# LRFDMDM register map
Vendor: Texas Instruments
Registers are 32-bit, access per field, reset 0x0 unless marked. A register's access mark holds for its fields unless they carry their own. Offsets are as the file gives them; [hi:lo] are bit positions; {n}, {i} and the like mark numbered series; 'fields as' and 'values as' point back to an identical list.

## LRFDMDM (part 3 of 3)
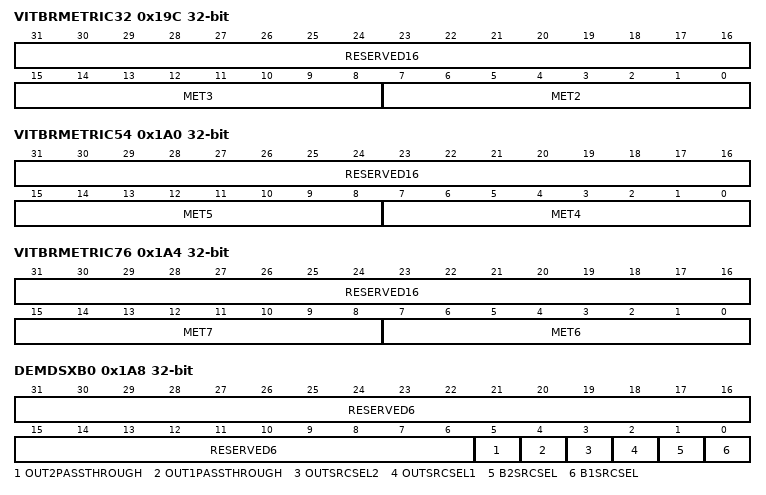
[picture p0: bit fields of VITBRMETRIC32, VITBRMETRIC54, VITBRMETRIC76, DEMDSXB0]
0x19C VITBRMETRIC32 — Internal. Only to be used through TI provided API.
  [31:16] RESERVED16 ro — Internal. Only to be used through TI provided API.
  [15:8] MET3 rw — Internal. Only to be used through TI provided API.
    255=ALLONES (Internal. Only to be used through TI provided API.); 0=ALLZEROS (Internal. Only to be used through TI provided API.)
  [7:0] MET2 rw — Internal. Only to be used through TI provided API.
    values as MET3
0x1A0 VITBRMETRIC54 — Internal. Only to be used through TI provided API.
  [31:16] RESERVED16 ro — Internal. Only to be used through TI provided API.
  [15:8] MET5 rw — Internal. Only to be used through TI provided API.
    values as VITBRMETRIC32.MET3
  [7:0] MET4 rw — Internal. Only to be used through TI provided API.
    values as VITBRMETRIC32.MET3
0x1A4 VITBRMETRIC76 — Internal. Only to be used through TI provided API.
  [31:16] RESERVED16 ro — Internal. Only to be used through TI provided API.
  [15:8] MET7 rw — Internal. Only to be used through TI provided API.
    values as VITBRMETRIC32.MET3
  [7:0] MET6 rw — Internal. Only to be used through TI provided API.
    values as VITBRMETRIC32.MET3
0x1A8 DEMDSXB0 — Internal. Only to be used through TI provided API.
  [31:6] RESERVED6 ro — Internal. Only to be used through TI provided API.
  [5] OUT2PASSTHROUGH rw — Internal. Only to be used through TI provided API.
    1=ONE (Internal. Only to be used through TI provided API.); 0=ZERO (Internal. Only to be used through TI provided API.)
  [4] OUT1PASSTHROUGH rw — Internal. Only to be used through TI provided API.
    values as OUT2PASSTHROUGH
  [3] OUTSRCSEL2 rw — Internal. Only to be used through TI provided API.
    1=MAFI (Internal. Only to be used through TI provided API.); 0=FIFE (Internal. Only to be used through TI provided API.)
  [2] OUTSRCSEL1 rw — Internal. Only to be used through TI provided API.
    values as OUTSRCSEL2
  [1] B2SRCSEL rw — Internal. Only to be used through TI provided API.
    1=FIFE (Internal. Only to be used through TI provided API.); 0=INPUT (Internal. Only to be used through TI provided API.)
  [0] B1SRCSEL rw — Internal. Only to be used through TI provided API.
    1=MAFI (Internal. Only to be used through TI provided API.); 0=INPUT (Internal. Only to be used through TI provided API.)
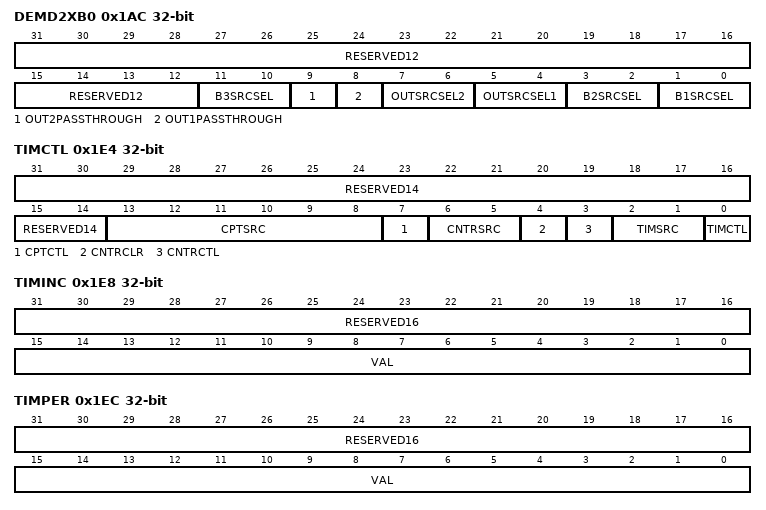
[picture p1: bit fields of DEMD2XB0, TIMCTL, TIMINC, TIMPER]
0x1AC DEMD2XB0 — Internal. Only to be used through TI provided API.
  [31:12] RESERVED12 ro — Internal. Only to be used through TI provided API.
  [11:10] B3SRCSEL rw — Internal. Only to be used through TI provided API.
    2=STIM (Internal. Only to be used through TI provided API.); 1=MAFC (Internal. Only to be used through TI provided API.); 0=INPUT (Internal. Only to be used through TI provided API.)
  [9] OUT2PASSTHROUGH rw — Internal. Only to be used through TI provided API.
  [8] OUT1PASSTHROUGH rw — Internal. Only to be used through TI provided API.
  [7:6] OUTSRCSEL2 rw — Internal. Only to be used through TI provided API.
    2=PDIF2 (Internal. Only to be used through TI provided API.); 1=STIM (Internal. Only to be used through TI provided API.); 0=MAFC (Internal. Only to be used through TI provided API.)
  [5:4] OUTSRCSEL1 rw — Internal. Only to be used through TI provided API.
    values as OUTSRCSEL2
  [3:2] B2SRCSEL rw — Internal. Only to be used through TI provided API.
    2=PDIF2 (Internal. Only to be used through TI provided API.); 1=MAFC (Internal. Only to be used through TI provided API.); 0=INPUT (Internal. Only to be used through TI provided API.)
  [1:0] B1SRCSEL rw — Internal. Only to be used through TI provided API.
    2=PDIF2 (Internal. Only to be used through TI provided API.); 1=STIM (Internal. Only to be used through TI provided API.); 0=INPUT (Internal. Only to be used through TI provided API.)
0x1E4 TIMCTL — Internal. Only to be used through TI provided API.
  [31:14] RESERVED14 ro — Internal. Only to be used through TI provided API.
  [13:8] CPTSRC rw — Internal. Only to be used through TI provided API.
    63=ALLONES (Internal. Only to be used through TI provided API.); 0=ALLZEROS (Internal. Only to be used through TI provided API.)
  [7] CPTCTL rw — Internal. Only to be used through TI provided API.
    1=EN (Internal. Only to be used through TI provided API.); 0=DIS (Internal. Only to be used through TI provided API.)
  [6:5] CNTRSRC rw — Internal. Only to be used through TI provided API.
    3=CLK4BAUDF (Internal. Only to be used through TI provided API.); 2=CLK4BAUD (Internal. Only to be used through TI provided API.); 1=CLKBAUD (Internal. Only to be used through TI provided API.); 0=CLK (Internal. Only to be used through TI provided API.)
  [4] CNTRCLR rw — Internal. Only to be used through TI provided API.
    values as DEMDSXB0.OUT2PASSTHROUGH
  [3] CNTRCTL rw — Internal. Only to be used through TI provided API.
    values as DEMDSXB0.OUT2PASSTHROUGH
  [2:1] TIMSRC rw — Internal. Only to be used through TI provided API.
    values as CNTRSRC
  [0] TIMCTL rw — Internal. Only to be used through TI provided API.
    values as CPTCTL
0x1E8 TIMINC — Internal. Only to be used through TI provided API.
  [31:16] RESERVED16 ro — Internal. Only to be used through TI provided API.
  [15:0] VAL rw — Internal. Only to be used through TI provided API.
    0xFFFF=ALLONES (Internal. Only to be used through TI provided API.); 0=ALLZEROS (Internal. Only to be used through TI provided API.)
0x1EC TIMPER — Internal. Only to be used through TI provided API.
  fields as TIMINC
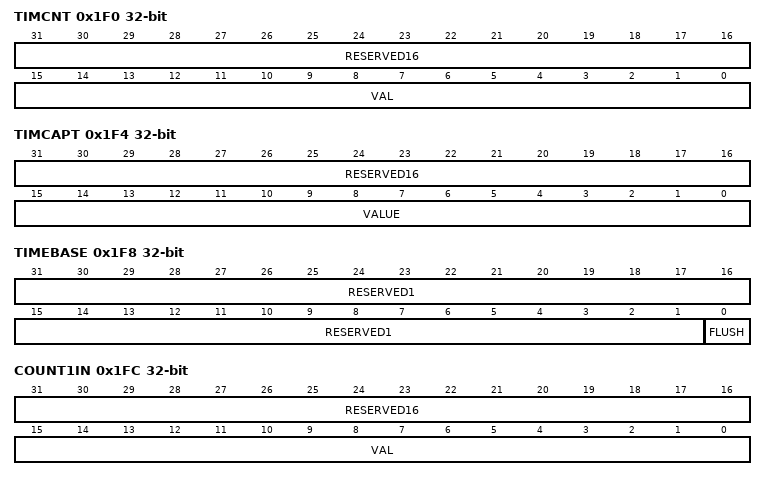
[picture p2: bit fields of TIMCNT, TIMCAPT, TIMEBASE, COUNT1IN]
0x1F0 TIMCNT ro — Internal. Only to be used through TI provided API.
  [31:16] RESERVED16 — Internal. Only to be used through TI provided API.
  [15:0] VAL — Internal. Only to be used through TI provided API.
    values as TIMINC.VAL
0x1F4 TIMCAPT ro — Internal. Only to be used through TI provided API.
  [31:16] RESERVED16 — Internal. Only to be used through TI provided API.
  [15:0] VALUE — Internal. Only to be used through TI provided API.
    values as TIMINC.VAL
0x1F8 TIMEBASE — Internal. Only to be used through TI provided API.
  [31:1] RESERVED1 ro — Internal. Only to be used through TI provided API.
  [0] FLUSH wo — Internal. Only to be used through TI provided API.
    values as DEMDSXB0.OUT2PASSTHROUGH
0x1FC COUNT1IN — Internal. Only to be used through TI provided API.
  fields as TIMINC
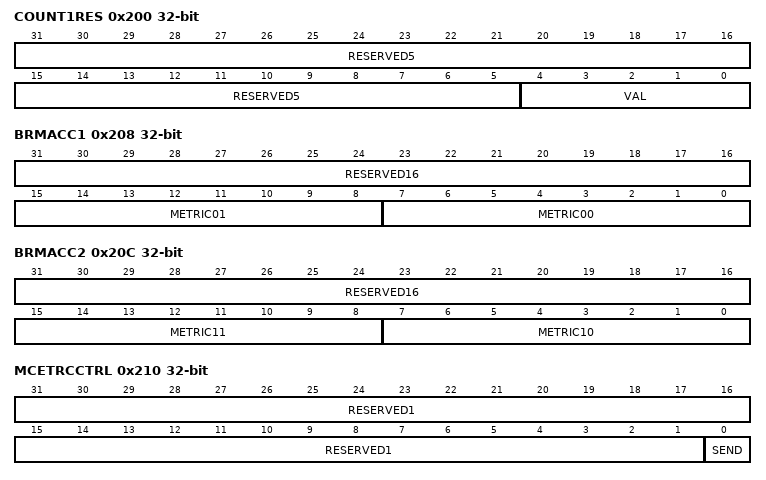
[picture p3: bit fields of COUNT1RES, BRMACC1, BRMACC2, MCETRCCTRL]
0x200 COUNT1RES ro — Internal. Only to be used through TI provided API.
  [31:5] RESERVED5 — Internal. Only to be used through TI provided API.
  [4:0] VAL — Internal. Only to be used through TI provided API.
    31=ALLONES (Internal. Only to be used through TI provided API.); 0=ALLZEROS (Internal. Only to be used through TI provided API.)
0x208 BRMACC1 ro — Internal. Only to be used through TI provided API.
  [31:16] RESERVED16 — Internal. Only to be used through TI provided API.
  [15:8] METRIC01 — Internal. Only to be used through TI provided API.
    values as VITBRMETRIC32.MET3
  [7:0] METRIC00 — Internal. Only to be used through TI provided API.
    values as VITBRMETRIC32.MET3
0x20C BRMACC2 ro — Internal. Only to be used through TI provided API.
  [31:16] RESERVED16 — Internal. Only to be used through TI provided API.
  [15:8] METRIC11 — Internal. Only to be used through TI provided API.
    values as VITBRMETRIC32.MET3
  [7:0] METRIC10 — Internal. Only to be used through TI provided API.
    values as VITBRMETRIC32.MET3
0x210 MCETRCCTRL — Internal. Only to be used through TI provided API.
  [31:1] RESERVED1 ro — Internal. Only to be used through TI provided API.
  [0] SEND wo — Internal. Only to be used through TI provided API.
    values as DEMDSXB0.OUT2PASSTHROUGH
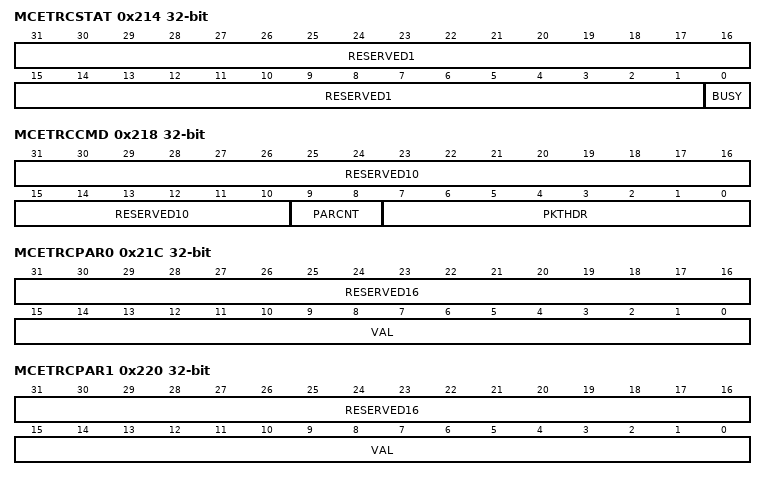
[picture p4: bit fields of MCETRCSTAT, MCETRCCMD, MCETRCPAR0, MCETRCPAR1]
0x214 MCETRCSTAT ro — Internal. Only to be used through TI provided API.
  [31:1] RESERVED1 — Internal. Only to be used through TI provided API.
  [0] BUSY — Internal. Only to be used through TI provided API.
    values as DEMDSXB0.OUT2PASSTHROUGH
0x218 MCETRCCMD — Internal. Only to be used through TI provided API.
  [31:10] RESERVED10 ro — Internal. Only to be used through TI provided API.
  [9:8] PARCNT rw — Internal. Only to be used through TI provided API.
    3=ALLONES (Internal. Only to be used through TI provided API.); 0=ALLZEROS (Internal. Only to be used through TI provided API.)
  [7:0] PKTHDR rw — Internal. Only to be used through TI provided API.
    values as VITBRMETRIC32.MET3
0x21C MCETRCPAR0 — Internal. Only to be used through TI provided API.
  fields as TIMINC
0x220 MCETRCPAR1 — Internal. Only to be used through TI provided API.
  fields as TIMINC
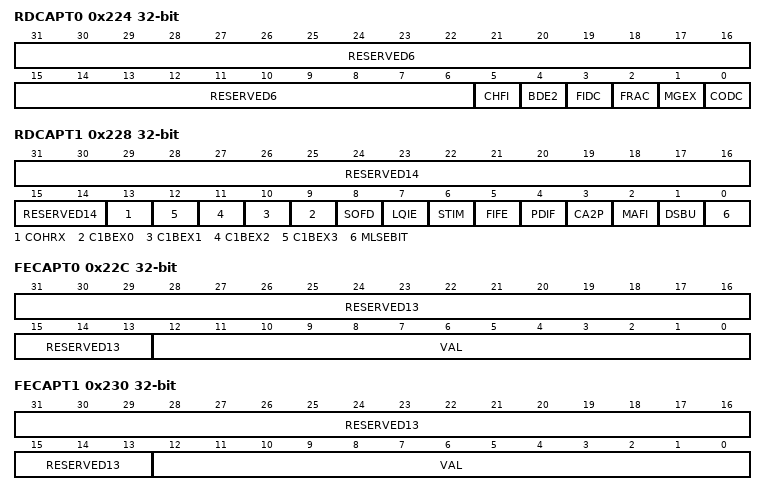
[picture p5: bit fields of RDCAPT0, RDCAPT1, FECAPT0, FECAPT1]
0x224 RDCAPT0 — Internal. Only to be used through TI provided API.
  [31:6] RESERVED6 ro — Internal. Only to be used through TI provided API.
  [5] CHFI wo — Internal. Only to be used through TI provided API.
    values as DEMDSXB0.OUT2PASSTHROUGH
  [4] BDE2 wo — Internal. Only to be used through TI provided API.
    values as DEMDSXB0.OUT2PASSTHROUGH
  [3] FIDC wo — Internal. Only to be used through TI provided API.
    values as DEMDSXB0.OUT2PASSTHROUGH
  [2] FRAC wo — Internal. Only to be used through TI provided API.
    values as DEMDSXB0.OUT2PASSTHROUGH
  [1] MGEX wo — Internal. Only to be used through TI provided API.
    values as DEMDSXB0.OUT2PASSTHROUGH
  [0] CODC wo — Internal. Only to be used through TI provided API.
    values as DEMDSXB0.OUT2PASSTHROUGH
0x228 RDCAPT1 — Internal. Only to be used through TI provided API.
  [31:14] RESERVED14 ro — Internal. Only to be used through TI provided API.
  [13] COHRX wo — Internal. Only to be used through TI provided API.
    values as DEMDSXB0.OUT2PASSTHROUGH
  [n+9] C1BEX{n} wo (n=0..3) — Internal. Only to be used through TI provided API.
    values as DEMDSXB0.OUT2PASSTHROUGH
  [8] SOFD wo — Internal. Only to be used through TI provided API.
    values as DEMDSXB0.OUT2PASSTHROUGH
  [7] LQIE wo — Internal. Only to be used through TI provided API.
    values as DEMDSXB0.OUT2PASSTHROUGH
  [6] STIM wo — Internal. Only to be used through TI provided API.
    values as DEMDSXB0.OUT2PASSTHROUGH
  [5] FIFE wo — Internal. Only to be used through TI provided API.
    values as DEMDSXB0.OUT2PASSTHROUGH
  [4] PDIF wo — Internal. Only to be used through TI provided API.
    values as DEMDSXB0.OUT2PASSTHROUGH
  [3] CA2P wo — Internal. Only to be used through TI provided API.
    values as DEMDSXB0.OUT2PASSTHROUGH
  [2] MAFI wo — Internal. Only to be used through TI provided API.
    values as DEMDSXB0.OUT2PASSTHROUGH
  [1] DSBU wo — Internal. Only to be used through TI provided API.
    values as DEMDSXB0.OUT2PASSTHROUGH
  [0] MLSEBIT wo — Internal. Only to be used through TI provided API.
    values as DEMDSXB0.OUT2PASSTHROUGH
0x22C FECAPT0 — Internal. Only to be used through TI provided API.
  [31:13] RESERVED13 ro — Internal. Only to be used through TI provided API.
  [12:0] VAL rw — Internal. Only to be used through TI provided API.
    0x1FFF=ALLONES (Internal. Only to be used through TI provided API.); 0=ALLZEROS (Internal. Only to be used through TI provided API.)
0x230 FECAPT1 — Internal. Only to be used through TI provided API.
  fields as FECAPT0
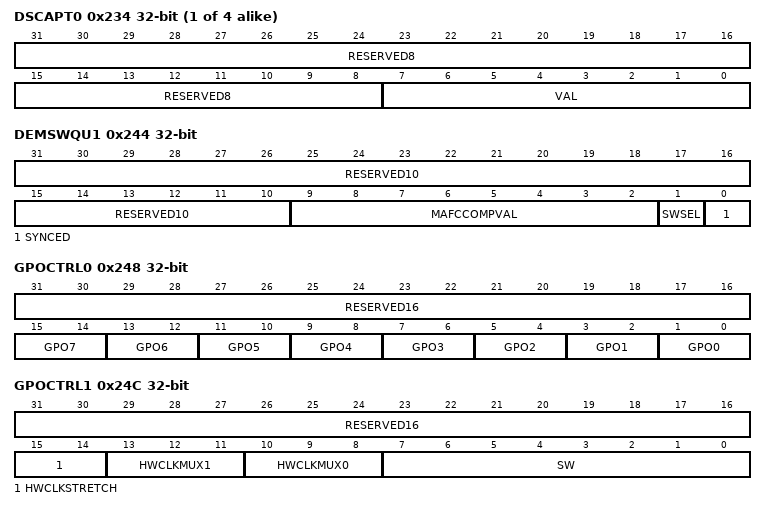
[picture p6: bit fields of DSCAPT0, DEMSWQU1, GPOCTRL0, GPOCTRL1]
{0x234+4i} DSCAPT{i} (i=0..3) — Internal. Only to be used through TI provided API.
  [31:8] RESERVED8 ro — Internal. Only to be used through TI provided API.
  [7:0] VAL rw — Internal. Only to be used through TI provided API.
    values as VITBRMETRIC32.MET3
0x244 DEMSWQU1 ro — Internal. Only to be used through TI provided API.
  [31:10] RESERVED10 — Internal. Only to be used through TI provided API.
  [9:2] MAFCCOMPVAL — Internal. Only to be used through TI provided API.
    values as VITBRMETRIC32.MET3
  [1] SWSEL — Internal. Only to be used through TI provided API.
    1=B (Internal. Only to be used through TI provided API.); 0=A (Internal. Only to be used through TI provided API.)
  [0] SYNCED — Internal. Only to be used through TI provided API.
    values as DEMDSXB0.OUT2PASSTHROUGH
0x248 GPOCTRL0 — Internal. Only to be used through TI provided API.
  [31:16] RESERVED16 ro — Internal. Only to be used through TI provided API.
  [15:14] GPO7 rw — Internal. Only to be used through TI provided API.
    3=THREE (Internal. Only to be used through TI provided API.); 2=TWO (Internal. Only to be used through TI provided API.); 1=TOPSM_WAIT (Internal. Only to be used through TI provided API.); 0=SW7 (Internal. Only to be used through TI provided API.)
  [13:12] GPO6 rw — Internal. Only to be used through TI provided API.
    3=THREE (Internal. Only to be used through TI provided API.); 2=TWO (Internal. Only to be used through TI provided API.); 1=TRANSPARENT_OUT (Internal. Only to be used through TI provided API.); 0=SW6 (Internal. Only to be used through TI provided API.)
  [11:10] GPO5 rw — Internal. Only to be used through TI provided API.
    3=THREE (Internal. Only to be used through TI provided API.); 2=TWO (Internal. Only to be used through TI provided API.); 1=DEM_OUT_WORD (Internal. Only to be used through TI provided API.); 0=SW5 (Internal. Only to be used through TI provided API.)
  [9:8] GPO4 rw — Internal. Only to be used through TI provided API.
    3=THREE (Internal. Only to be used through TI provided API.); 2=TWO (Internal. Only to be used through TI provided API.); 1=CORR_PEAK_C (Internal. Only to be used through TI provided API.); 0=SW4 (Internal. Only to be used through TI provided API.)
  [7:6] GPO3 rw — Internal. Only to be used through TI provided API.
    3=THREE (Internal. Only to be used through TI provided API.); 2=TWO (Internal. Only to be used through TI provided API.); 1=CORR_PEAK_B (Internal. Only to be used through TI provided API.); 0=SW3 (Internal. Only to be used through TI provided API.)
  [5:4] GPO2 rw — Internal. Only to be used through TI provided API.
    3=THREE (Internal. Only to be used through TI provided API.); 2=TWO (Internal. Only to be used through TI provided API.); 1=CORR_PEAK_A (Internal. Only to be used through TI provided API.); 0=SW2 (Internal. Only to be used through TI provided API.)
  [3:2] GPO1 rw — Internal. Only to be used through TI provided API.
    3=THREE (Internal. Only to be used through TI provided API.); 2=TWO (Internal. Only to be used through TI provided API.); 1=HWCLK1 (Internal. Only to be used through TI provided API.); 0=SW1 (Internal. Only to be used through TI provided API.)
  [1:0] GPO0 rw — Internal. Only to be used through TI provided API.
    3=THREE (Internal. Only to be used through TI provided API.); 2=LOOPBACK (Internal. Only to be used through TI provided API.); 1=HWCLK0 (Internal. Only to be used through TI provided API.); 0=SW0 (Internal. Only to be used through TI provided API.)
0x24C GPOCTRL1 — Internal. Only to be used through TI provided API.
  [31:16] RESERVED16 ro — Internal. Only to be used through TI provided API.
  [15:14] HWCLKSTRETCH rw — Internal. Only to be used through TI provided API.
    values as DEMDSXB0.OUT2PASSTHROUGH
  [13:11] HWCLKMUX1 rw — Internal. Only to be used through TI provided API.
    values as DEMDSXB0.OUT2PASSTHROUGH
  [10:8] HWCLKMUX0 rw — Internal. Only to be used through TI provided API.
    values as DEMDSXB0.OUT2PASSTHROUGH
  [7:0] SW rw — Internal. Only to be used through TI provided API.
    values as DEMDSXB0.OUT2PASSTHROUGH
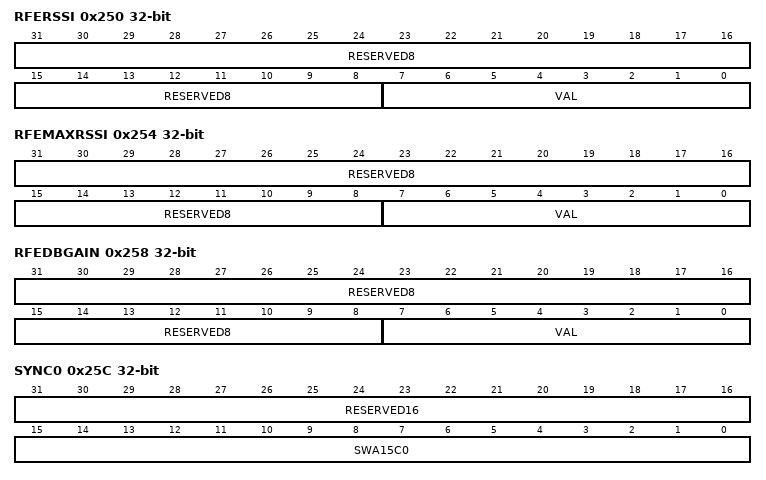
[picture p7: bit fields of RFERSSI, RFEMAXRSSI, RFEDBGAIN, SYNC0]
0x250 RFERSSI ro — Internal. Only to be used through TI provided API.
  [31:8] RESERVED8 — Internal. Only to be used through TI provided API.
  [7:0] VAL — Internal. Only to be used through TI provided API.
    values as VITBRMETRIC32.MET3
0x254 RFEMAXRSSI ro — Internal. Only to be used through TI provided API.
  fields as RFERSSI
0x258 RFEDBGAIN ro — Internal. Only to be used through TI provided API.
  fields as RFERSSI
0x25C SYNC0 ro — Internal. Only to be used through TI provided API.
  [31:16] RESERVED16 — Internal. Only to be used through TI provided API.
  [15:0] SWA15C0 — Internal. Only to be used through TI provided API.
    values as TIMINC.VAL
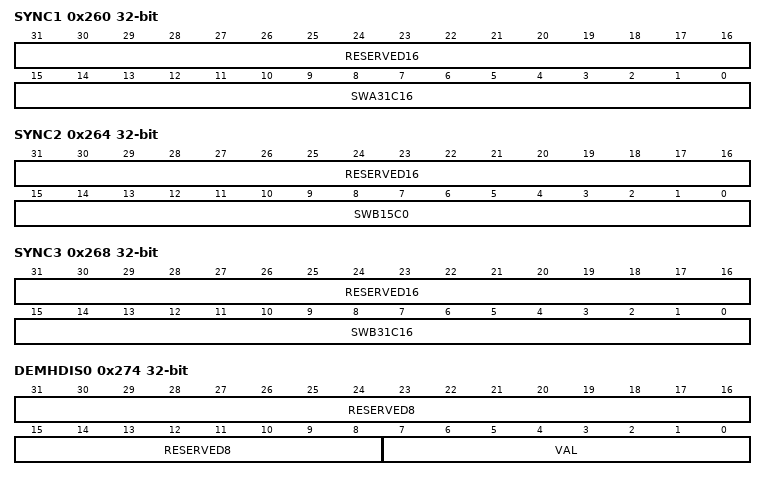
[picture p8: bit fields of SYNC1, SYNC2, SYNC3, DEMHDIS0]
0x260 SYNC1 ro — Internal. Only to be used through TI provided API.
  [31:16] RESERVED16 — Internal. Only to be used through TI provided API.
  [15:0] SWA31C16 — Internal. Only to be used through TI provided API.
    values as TIMINC.VAL
0x264 SYNC2 ro — Internal. Only to be used through TI provided API.
  [31:16] RESERVED16 — Internal. Only to be used through TI provided API.
  [15:0] SWB15C0 — Internal. Only to be used through TI provided API.
    values as TIMINC.VAL
0x268 SYNC3 ro — Internal. Only to be used through TI provided API.
  [31:16] RESERVED16 — Internal. Only to be used through TI provided API.
  [15:0] SWB31C16 — Internal. Only to be used through TI provided API.
    values as TIMINC.VAL
0x274 DEMHDIS0 ro — Internal. Only to be used through TI provided API.
  [31:8] RESERVED8 — Internal. Only to be used through TI provided API.
  [7:0] VAL — Internal. Only to be used through TI provided API.
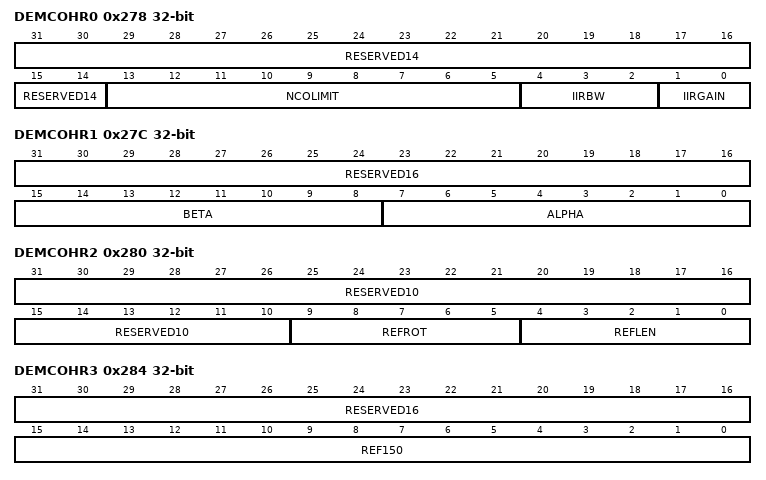
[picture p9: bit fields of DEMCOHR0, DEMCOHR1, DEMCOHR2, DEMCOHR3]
0x278 DEMCOHR0 — Internal. Only to be used through TI provided API.
  [31:14] RESERVED14 ro — Internal. Only to be used through TI provided API.
  [13:5] NCOLIMIT rw — Internal. Only to be used through TI provided API.
  [4:2] IIRBW rw — Internal. Only to be used through TI provided API.
  [1:0] IIRGAIN rw — Internal. Only to be used through TI provided API.
0x27C DEMCOHR1 — Internal. Only to be used through TI provided API.
  [31:16] RESERVED16 ro — Internal. Only to be used through TI provided API.
  [15:8] BETA rw — Internal. Only to be used through TI provided API.
  [7:0] ALPHA rw — Internal. Only to be used through TI provided API.
0x280 DEMCOHR2 — Internal. Only to be used through TI provided API.
  [31:10] RESERVED10 ro — Internal. Only to be used through TI provided API.
  [9:5] REFROT rw — Internal. Only to be used through TI provided API.
  [4:0] REFLEN rw — Internal. Only to be used through TI provided API.
0x284 DEMCOHR3 — Internal. Only to be used through TI provided API.
  [31:16] RESERVED16 ro — Internal. Only to be used through TI provided API.
  [15:0] REF150 rw — Internal. Only to be used through TI provided API.
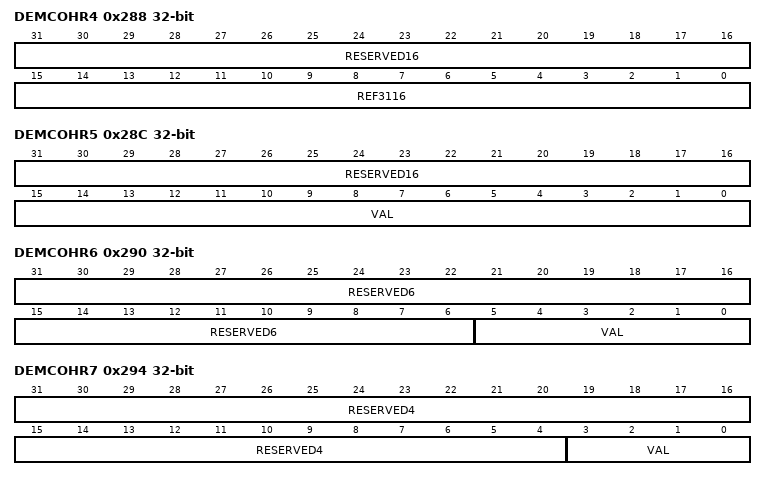
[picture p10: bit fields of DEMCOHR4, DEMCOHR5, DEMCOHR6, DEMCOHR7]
0x288 DEMCOHR4 — Internal. Only to be used through TI provided API.
  [31:16] RESERVED16 ro — Internal. Only to be used through TI provided API.
  [15:0] REF3116 rw — Internal. Only to be used through TI provided API.
0x28C DEMCOHR5 ro — Internal. Only to be used through TI provided API.
  [31:16] RESERVED16 — Internal. Only to be used through TI provided API.
  [15:0] VAL — Internal. Only to be used through TI provided API.
0x290 DEMCOHR6 ro — Internal. Only to be used through TI provided API.
  [31:6] RESERVED6 — Internal. Only to be used through TI provided API.
  [5:0] VAL — Internal. Only to be used through TI provided API.
0x294 DEMCOHR7 ro — Internal. Only to be used through TI provided API.
  [31:4] RESERVED4 — Internal. Only to be used through TI provided API.
  [3:0] VAL — Internal. Only to be used through TI provided API.
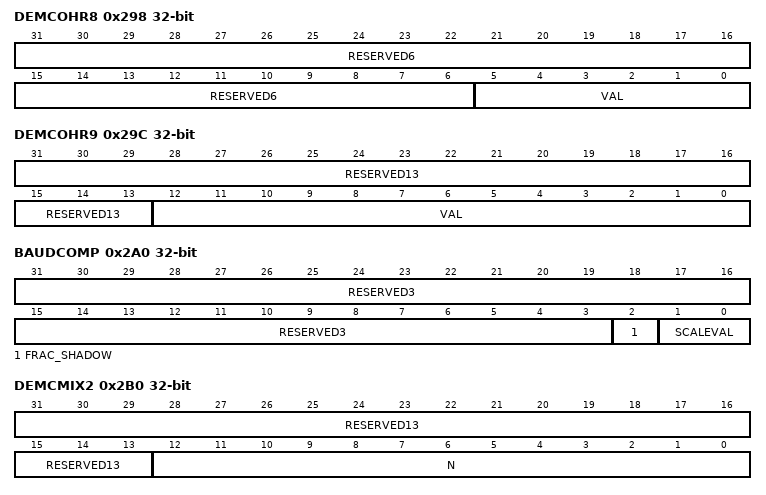
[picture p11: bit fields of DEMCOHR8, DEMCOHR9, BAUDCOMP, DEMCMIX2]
0x298 DEMCOHR8 ro — Internal. Only to be used through TI provided API.
  fields as DEMCOHR6
0x29C DEMCOHR9 ro — Internal. Only to be used through TI provided API.
  [31:13] RESERVED13 — Internal. Only to be used through TI provided API.
  [12:0] VAL — Internal. Only to be used through TI provided API.
0x2A0 BAUDCOMP — Internal. Only to be used through TI provided API.
  [31:3] RESERVED3 ro — Internal. Only to be used through TI provided API.
  [2] FRAC_SHADOW rw — Internal. Only to be used through TI provided API.
  [1:0] SCALEVAL rw — Internal. Only to be used through TI provided API.
0x2B0 DEMCMIX2 — Internal. Only to be used through TI provided API.
  [31:13] RESERVED13 ro — Internal. Only to be used through TI provided API.
  [12:0] N rw — Internal. Only to be used through TI provided API.
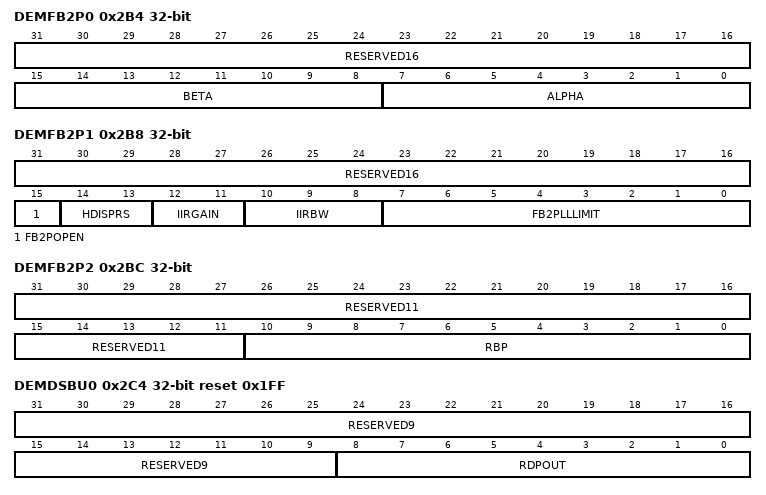
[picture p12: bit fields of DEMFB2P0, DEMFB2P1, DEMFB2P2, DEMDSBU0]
0x2B4 DEMFB2P0 — Internal. Only to be used through TI provided API.
  fields as DEMCOHR1
0x2B8 DEMFB2P1 — Internal. Only to be used through TI provided API.
  [31:16] RESERVED16 ro — Internal. Only to be used through TI provided API.
  [15] FB2POPEN rw — Internal. Only to be used through TI provided API.
  [14:13] HDISPRS rw — Internal. Only to be used through TI provided API.
  [12:11] IIRGAIN rw — Internal. Only to be used through TI provided API.
  [10:8] IIRBW rw — Internal. Only to be used through TI provided API.
  [7:0] FB2PLLLIMIT rw — Internal. Only to be used through TI provided API.
0x2BC DEMFB2P2 ro — Internal. Only to be used through TI provided API.
  [31:11] RESERVED11 — Internal. Only to be used through TI provided API.
  [10:0] RBP — Internal. Only to be used through TI provided API.
0x2C4 DEMDSBU0 ro reset 0x1FF — Internal. Only to be used through TI provided API.
  [31:9] RESERVED9 — Internal. Only to be used through TI provided API.
  [8:0] RDPOUT — Internal. Only to be used through TI provided API.
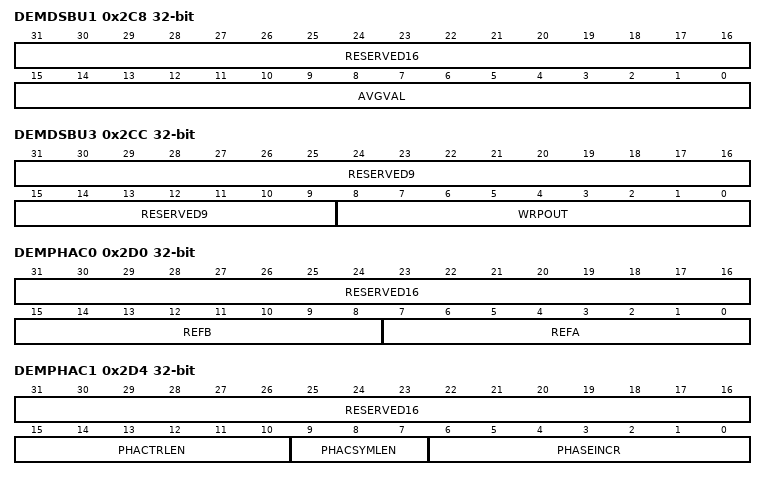
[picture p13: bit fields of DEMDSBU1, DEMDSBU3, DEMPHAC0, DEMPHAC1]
0x2C8 DEMDSBU1 ro — Internal. Only to be used through TI provided API.
  [31:16] RESERVED16 — Internal. Only to be used through TI provided API.
  [15:0] AVGVAL — Internal. Only to be used through TI provided API.
0x2CC DEMDSBU3 ro — Internal. Only to be used through TI provided API.
  [31:9] RESERVED9 — Internal. Only to be used through TI provided API.
  [8:0] WRPOUT — Internal. Only to be used through TI provided API.
0x2D0 DEMPHAC0 — Internal. Only to be used through TI provided API.
  [31:16] RESERVED16 ro — Internal. Only to be used through TI provided API.
  [15:8] REFB rw — Internal. Only to be used through TI provided API.
  [7:0] REFA rw — Internal. Only to be used through TI provided API.
0x2D4 DEMPHAC1 — Internal. Only to be used through TI provided API.
  [31:16] RESERVED16 ro — Internal. Only to be used through TI provided API.
  [15:10] PHACTRLEN rw — Internal. Only to be used through TI provided API.
  [9:7] PHACSYMLEN rw — Internal. Only to be used through TI provided API.
  [6:0] PHASEINCR rw — Internal. Only to be used through TI provided API.
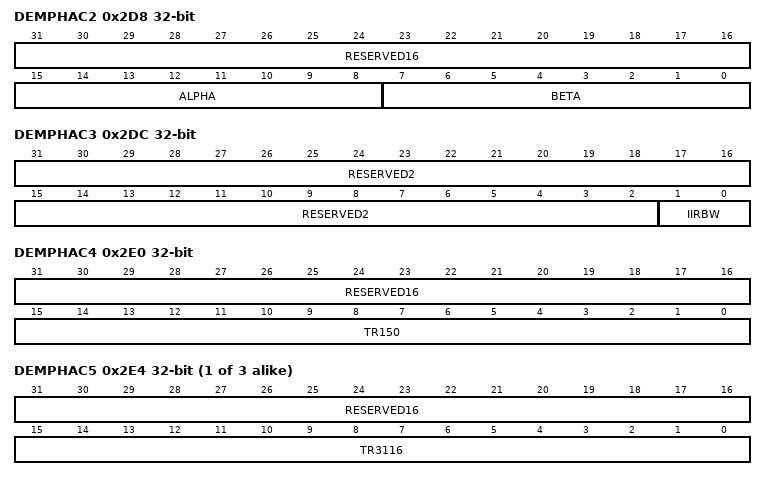
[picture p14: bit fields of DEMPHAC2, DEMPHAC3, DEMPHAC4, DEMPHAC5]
0x2D8 DEMPHAC2 — Internal. Only to be used through TI provided API.
  [31:16] RESERVED16 ro — Internal. Only to be used through TI provided API.
  [15:8] ALPHA rw — Internal. Only to be used through TI provided API.
  [7:0] BETA rw — Internal. Only to be used through TI provided API.
0x2DC DEMPHAC3 — Internal. Only to be used through TI provided API.
  [31:2] RESERVED2 ro — Internal. Only to be used through TI provided API.
  [1:0] IIRBW rw — Internal. Only to be used through TI provided API.
0x2E0 DEMPHAC4 — Internal. Only to be used through TI provided API.
  [31:16] RESERVED16 ro — Internal. Only to be used through TI provided API.
  [15:0] TR150 rw — Internal. Only to be used through TI provided API.
{0x2D0+4i} DEMPHAC{i} (i=5..7) — Internal. Only to be used through TI provided API.
  [31:16] RESERVED16 ro — Internal. Only to be used through TI provided API.
  [15:0] TR{1616i-4964} rw — Internal. Only to be used through TI provided API.
0x2F0 DEMPHAC8 ro — Internal. Only to be used through TI provided API.
  [31:16] RESERVED16 — Internal. Only to be used through TI provided API.
  [15:8] METRIC01 — Internal. Only to be used through TI provided API.
  [7:0] METRIC00 — Internal. Only to be used through TI provided API.
0x2F4 DEMPHAC9 ro — Internal. Only to be used through TI provided API.
  [31:16] RESERVED16 — Internal. Only to be used through TI provided API.
  [15:8] METRIC11 — Internal. Only to be used through TI provided API.
  [7:0] METRIC10 — Internal. Only to be used through TI provided API.
0x2F8 DEMC1BEREF4 — Internal. Only to be used through TI provided API.
  [31:16] RESERVED16 ro — Internal. Only to be used through TI provided API.
  [15:0] CDR15C0 rw — Internal. Only to be used through TI provided API.
0x2FC DEMC1BEREF5 — Internal. Only to be used through TI provided API.
  [31:16] RESERVED16 ro — Internal. Only to be used through TI provided API.
  [15:0] CDR31C16 rw — Internal. Only to be used through TI provided API.
0x300 DEMC1BEREF6 — Internal. Only to be used through TI provided API.
  [31:16] RESERVED16 ro — Internal. Only to be used through TI provided API.
  [15:0] CER15C0 rw — Internal. Only to be used through TI provided API.
0x304 DEMC1BEREF7 — Internal. Only to be used through TI provided API.
  [31:16] RESERVED16 ro — Internal. Only to be used through TI provided API.
  [15:0] CER31C16 rw — Internal. Only to be used through TI provided API.
0x308 DEMC1BE3 ro — Internal. Only to be used through TI provided API.
  [31:16] RESERVED16 — Internal. Only to be used through TI provided API.
  [15:0] CORRVALUEA — Internal. Only to be used through TI provided API.
0x30C DEMC1BE4 ro — Internal. Only to be used through TI provided API.
  [31:16] RESERVED16 — Internal. Only to be used through TI provided API.
  [15:0] CORRVALUEB — Internal. Only to be used through TI provided API.
0x310 DEMC1BE5 ro — Internal. Only to be used through TI provided API.
  [31:16] RESERVED16 — Internal. Only to be used through TI provided API.
  [15:0] CORRVALUEC — Internal. Only to be used through TI provided API.
{0x2FC+4i} DEMC1BE{i} ro (i=6..9) — Internal. Only to be used through TI provided API.
  fields as DEMHDIS0
0x324 DEMC1BE10 — Internal. Only to be used through TI provided API.
  [31:16] RESERVED16 ro — Internal. Only to be used through TI provided API.
  [15] PEAKCONFG rw — Internal. Only to be used through TI provided API.
  [14:13] PEAKCONFCF rw — Internal. Only to be used through TI provided API.
    2=BESTAB (Internal. Only to be used through TI provided API.); 1=BEST (Internal. Only to be used through TI provided API.); 0=THRESH (Internal. Only to be used through TI provided API.)
  [12:8] MASKE rw — Internal. Only to be used through TI provided API.
  [7:3] MASKD rw — Internal. Only to be used through TI provided API.
  [2:0] CASCCONF rw — Internal. Only to be used through TI provided API.
    5=SINGLE2 (Internal. Only to be used through TI provided API.); 4=SERIAL2 (Internal. Only to be used through TI provided API.); 3=SINGLE (Internal. Only to be used through TI provided API.); 2=PARALLEL (Internal. Only to be used through TI provided API.); 1=SERIAL (Internal. Only to be used through TI provided API.); 0=DISABLED (Internal. Only to be used through TI provided API.)
0x328 DEMC1BE11 — Internal. Only to be used through TI provided API.
  [31:16] RESERVED16 ro — Internal. Only to be used through TI provided API.
  [15:8] THRESHOLDE rw — Internal. Only to be used through TI provided API.
  [7:0] THRESHOLDD rw — Internal. Only to be used through TI provided API.
0x32C DEMC1BE12 — Internal. Only to be used through TI provided API.
  [31:16] RESERVED16 ro — Internal. Only to be used through TI provided API.
  [15:8] THRESHOLDG rw — Internal. Only to be used through TI provided API.
  [7:0] THRESHOLDF rw — Internal. Only to be used through TI provided API.
0x330 DEMC1BE13 ro — Internal. Only to be used through TI provided API.
  [31:16] RESERVED16 — Internal. Only to be used through TI provided API.
  [15:0] CORRVALUED — Internal. Only to be used through TI provided API.
0x334 DEMC1BE14 ro — Internal. Only to be used through TI provided API.
  [31:16] RESERVED16 — Internal. Only to be used through TI provided API.
  [15:0] CORRVALUEE — Internal. Only to be used through TI provided API.
0x338 DEMC1BE15 ro — Internal. Only to be used through TI provided API.
  [31:16] RESERVED16 — Internal. Only to be used through TI provided API.
  [15:0] CORRVALUEF — Internal. Only to be used through TI provided API.
0x34C DEMC1BE20 ro — Internal. Only to be used through TI provided API.
  [31:16] RESERVED16 — Internal. Only to be used through TI provided API.
  [15:0] CORRVALUEG — Internal. Only to be used through TI provided API.
0x354 STRB2 — Internal. Only to be used through TI provided API.
  [31:6] RESERVED6 ro — Internal. Only to be used through TI provided API.
  [5] C1BECOPY2 wo — Internal. Only to be used through TI provided API.
    values as DEMDSXB0.OUT2PASSTHROUGH
  [4] C1BEPEAKG wo — Internal. Only to be used through TI provided API.
    values as DEMDSXB0.OUT2PASSTHROUGH
  [3] C1BEPEAKDE wo — Internal. Only to be used through TI provided API.
    values as DEMDSXB0.OUT2PASSTHROUGH
  [2] C1BEPEAKF wo — Internal. Only to be used through TI provided API.
    values as DEMDSXB0.OUT2PASSTHROUGH
  [1] C1BEPEAKE wo — Internal. Only to be used through TI provided API.
    values as DEMDSXB0.OUT2PASSTHROUGH
  [0] C1BEPEAKD wo — Internal. Only to be used through TI provided API.
    values as DEMDSXB0.OUT2PASSTHROUGH
0x358 EVT3 ro — Internal. Only to be used through TI provided API.
  [31:16] RESERVED16 — Internal. Only to be used through TI provided API.
  [15] C1BEDLOADED — Internal. Only to be used through TI provided API.
    values as DEMDSXB0.OUT2PASSTHROUGH
  [14] C1BEGANY — Internal. Only to be used through TI provided API.
  [13] C1BEGNEG — Internal. Only to be used through TI provided API.
  [12] C1BEGPOS — Internal. Only to be used through TI provided API.
  [11] C1BECMBDEANY — Internal. Only to be used through TI provided API.
  [10] C1BECMBDENEG — Internal. Only to be used through TI provided API.
  [9] C1BECMBDEPOS — Internal. Only to be used through TI provided API.
  [8] C1BEFANY — Internal. Only to be used through TI provided API.
  [7] C1BEFNEG — Internal. Only to be used through TI provided API.
  [6] C1BEFPOS — Internal. Only to be used through TI provided API.
  [5] C1BEEANY — Internal. Only to be used through TI provided API.
  [4] C1BEENEG — Internal. Only to be used through TI provided API.
  [3] C1BEEPOS — Internal. Only to be used through TI provided API.
  [2] C1BEDANY — Internal. Only to be used through TI provided API.
  [1] C1BEDNEG — Internal. Only to be used through TI provided API.
  [0] C1BEDPOS — Internal. Only to be used through TI provided API.
0x35C EVTMSK3 — Internal. Only to be used through TI provided API.
  [31:16] RESERVED16 ro — Internal. Only to be used through TI provided API.
  [15] C1BEDLOADED rw — Internal. Only to be used through TI provided API.
  [14] C1BEGANY rw — Internal. Only to be used through TI provided API.
  [13] C1BEGNEG rw — Internal. Only to be used through TI provided API.
  [12] C1BEGPOS rw — Internal. Only to be used through TI provided API.
  [11] C1BECMBDEANY rw — Internal. Only to be used through TI provided API.
  [10] C1BECMBDENEG rw — Internal. Only to be used through TI provided API.
  [9] C1BECMBDEPOS rw — Internal. Only to be used through TI provided API.
  [8] C1BEFANY rw — Internal. Only to be used through TI provided API.
  [7] C1BEFNEG rw — Internal. Only to be used through TI provided API.
  [6] C1BEFPOS rw — Internal. Only to be used through TI provided API.
  [5] C1BEEANY rw — Internal. Only to be used through TI provided API.
  [4] C1BEENEG rw — Internal. Only to be used through TI provided API.
  [3] C1BEEPOS rw — Internal. Only to be used through TI provided API.
  [2] C1BEDANY rw — Internal. Only to be used through TI provided API.
  [1] C1BEDNEG rw — Internal. Only to be used through TI provided API.
  [0] C1BEDPOS rw — Internal. Only to be used through TI provided API.
0x360 EVTCLR3 — Internal. Only to be used through TI provided API.
  [31:16] RESERVED16 ro — Internal. Only to be used through TI provided API.
  [15] C1BEDLOADED wo — Internal. Only to be used through TI provided API.
  [14] C1BEGANY wo — Internal. Only to be used through TI provided API.
  [13] C1BEGNEG wo — Internal. Only to be used through TI provided API.
  [12] C1BEGPOS wo — Internal. Only to be used through TI provided API.
  [11] C1BECMBDEANY wo — Internal. Only to be used through TI provided API.
  [10] C1BECMBDENEG wo — Internal. Only to be used through TI provided API.
  [9] C1BECMBDEPOS wo — Internal. Only to be used through TI provided API.
  [8] C1BEFANY wo — Internal. Only to be used through TI provided API.
  [7] C1BEFNEG wo — Internal. Only to be used through TI provided API.
  [6] C1BEFPOS wo — Internal. Only to be used through TI provided API.
  [5] C1BEEANY wo — Internal. Only to be used through TI provided API.
  [4] C1BEENEG wo — Internal. Only to be used through TI provided API.
  [3] C1BEEPOS wo — Internal. Only to be used through TI provided API.
  [2] C1BEDANY wo — Internal. Only to be used through TI provided API.
  [1] C1BEDNEG wo — Internal. Only to be used through TI provided API.
  [0] C1BEDPOS wo — Internal. Only to be used through TI provided API.
